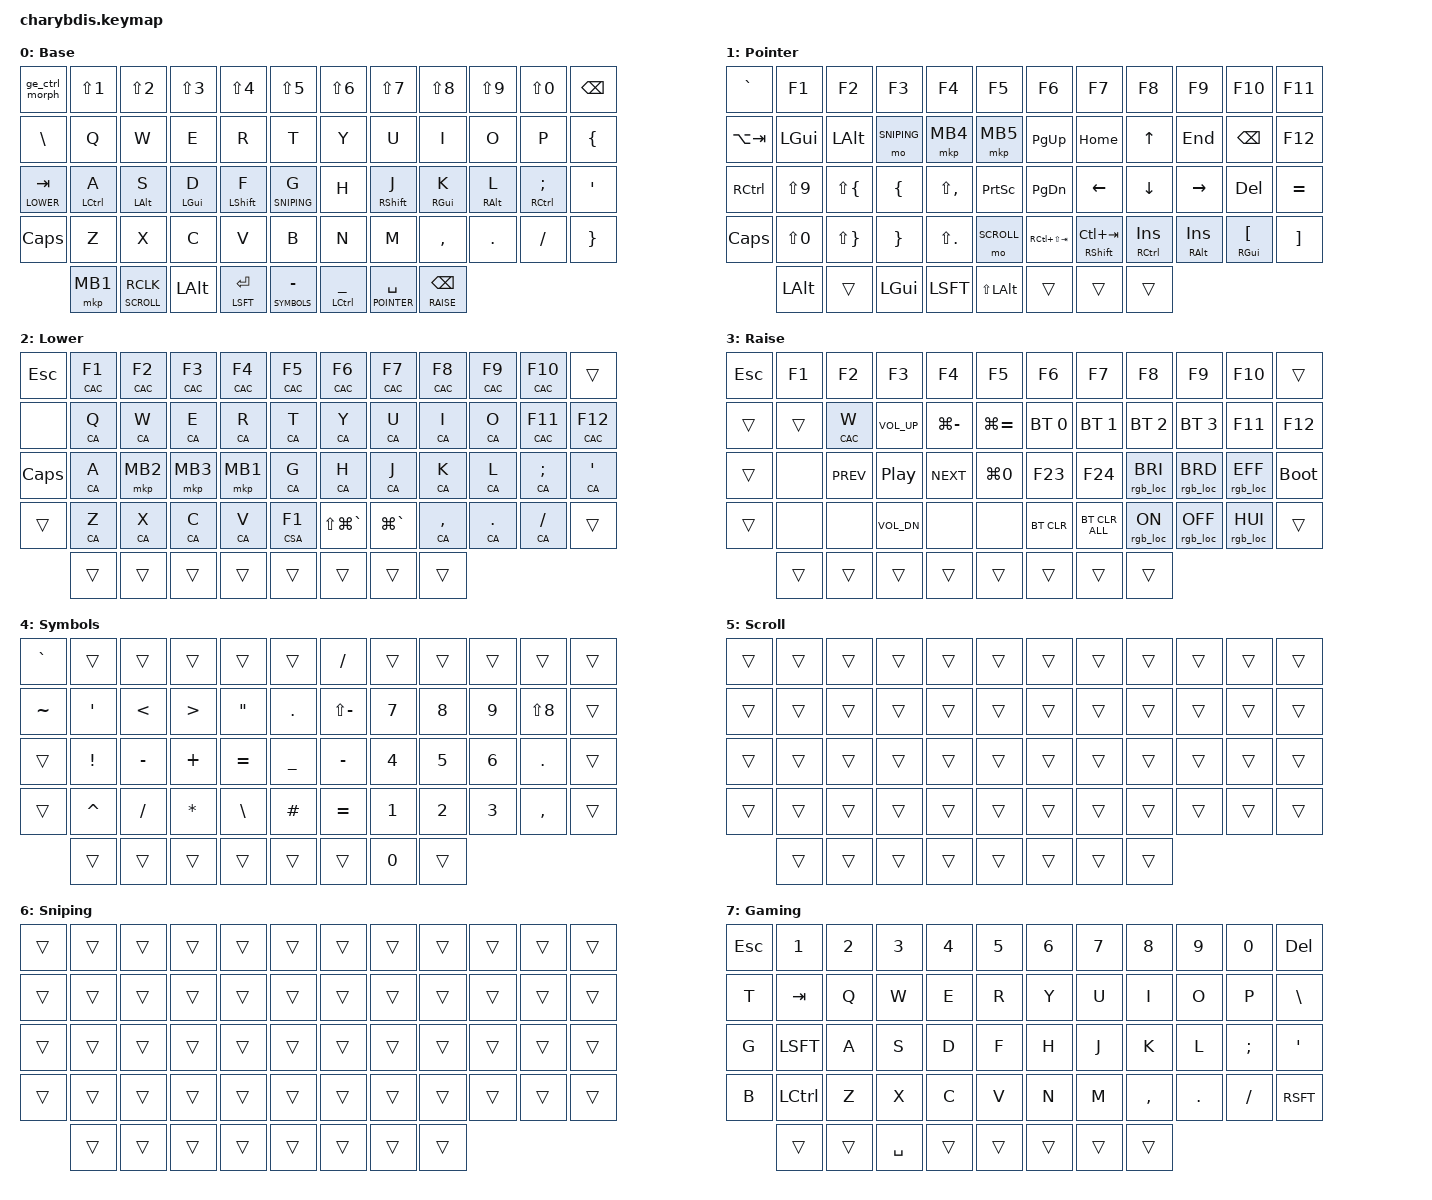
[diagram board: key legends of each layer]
#include <dt-bindings/zmk/mouse.h>
#include <behaviors/mouse_keys.dtsi>
#include <behaviors.dtsi>
#include <dt-bindings/zmk/bt.h>
#include <dt-bindings/zmk/keys.h>
#include <dt-bindings/zmk/modifiers.h>
#include <dt-bindings/zmk/outputs.h>
#include <dt-bindings/zmk/pointing.h>
#include <dt-bindings/zmk/rgb.h>

/ {
    chosen { zmk,physical-layout = &charybdis_6col_layout; };
};

&mt {
    quick-tap-ms = <200>;
    flavor = "tap-preferred";
    tapping-term-ms = <170>;
};

&lt {
    quick-tap-ms = <200>;
    flavor = "tap-preferred";
    tapping-term-ms = <170>;
};

// Layer definitions
#define BASE 0
#define POINTER 1
#define LOWER 2
#define RAISE 3
#define SYMBOLS 4
#define SCROLL 5
#define SNIPING 6
#define GAMING 7

/ {
  behaviors {
    // Hold-tap behavior for layer with tap-preferred
    blt: blt {
      compatible = "zmk,behavior-hold-tap";
      #binding-cells = <2>;
      flavor = "tap-preferred";
      tapping-term-ms = <200>;
      quick-tap-ms = <300>;
      require-prior-idle-ms = <100>;
      bindings = <&mo>, <&kp>;
    };

    // Tap-dance for GUI/Ctrl+B
    gui_ctrlb: gui_ctrlb {
      compatible = "zmk,behavior-tap-dance";
      #binding-cells = <0>;
      tapping-term-ms = <200>;
      bindings = <&kp LGUI>, <&kp LC(B)>;
    };

    // Tap/hold Alt, double-tap Ctrl+Shift+Z
    lalt_dt: lalt_dt {
      compatible = "zmk,behavior-tap-dance";
      #binding-cells = <0>;
      tapping-term-ms = <200>;
      bindings = <&kp LALT>, <&kp LC(LS(Z))>;
    };

    // Home row mods - Left hand
    hml: home_row_mod_left {
      compatible = "zmk,behavior-hold-tap";
      #binding-cells = <2>;
      flavor = "balanced";
      require-prior-idle-ms = <150>;
      tapping-term-ms = <280>;
      quick-tap-ms = <175>;
      bindings = <&kp>, <&kp>;
      hold-trigger-key-positions = <6 7 8 9 10 11 18 19 20 21 22 23 30 31 32 33 34 35 42 43 44 45 46 47 53 54 55>; // Right side keys
      hold-trigger-on-release;
    };

    // Home row mods - Right hand
    hmr: home_row_mod_right {
      compatible = "zmk,behavior-hold-tap";
      #binding-cells = <2>;
      flavor = "balanced";
      require-prior-idle-ms = <150>;
      tapping-term-ms = <280>;
      quick-tap-ms = <175>;
      bindings = <&kp>, <&kp>;
      hold-trigger-key-positions = <0 1 2 3 4 5 12 13 14 15 16 17 24 25 26 27 28 29 36 37 38 39 40 41 48 49 50 51 52>; // Left side keys
      hold-trigger-on-release;
    };

    // RGB controls routed globally so split halves stay in sync.
    rgb_loc: rgbloc {
      compatible = "zmk,behavior-rgb-local";
      #binding-cells = <2>;
    };

    // RGB controls: dedicated direct bindings.
    // 1. Сначала обрабатываем нажатие с Ctrl: если зажат Ctrl, отправляем `, иначе переходим к проверке Shift
    ge_ctrl_morph: ge_ctrl_morph {
        compatible = "zmk,behavior-mod-morph";
        #binding-cells = <0>;
        bindings = <&ge_shift_morph>, <&kp GRAVE>;
        mods = <(MOD_LCTL|MOD_RCTL)>;
        keep-mods = <0>; // Убирает Ctrl, чтобы напечатался чистый символ `
    };

    // 2. Проверяем Shift: если зажат Shift, отправляем ~, если ничего не зажато — отправляем ESC
    ge_shift_morph: ge_shift_morph {
        compatible = "zmk,behavior-mod-morph";
        #binding-cells = <0>;
        bindings = <&kp ESC>, <&kp TILDE>;
        mods = <(MOD_LSFT|MOD_RSFT)>;
        keep-mods = <0>; // Убирает Shift, чтобы напечаталась чистая тильда ~
    };  

    // Special behavior, smart analog of Layer-Tap, but here the second action is a mouse button
    blt_mouse: blt_mouse {
          compatible = "zmk,behavior-hold-tap";
          #binding-cells = <2>;
          flavor = "tap-preferred";
          tapping-term-ms = <200>;
          quick-tap-ms = <300>;
          require-prior-idle-ms = <100>;
          bindings = <&mo>, <&mkp>; // <- CRITICAL: keep &mkp instead of &kp
        };

  };

  macros {
    // Ctrl+Alt+Cmd macro
    CAC: CAC {
      compatible = "zmk,behavior-macro-one-param";
      #binding-cells = <1>;
      bindings
        = <&macro_press &kp LCTRL &kp LALT &kp LGUI>
        , <&macro_param_1to1>
        , <&macro_tap &kp MACRO_PLACEHOLDER>
        , <&macro_release &kp LCTRL &kp LALT &kp LGUI>
        ;
    };

    // Ctrl+Shift+Alt macro
    CSA: CSA {
      compatible = "zmk,behavior-macro-one-param";
      #binding-cells = <1>;
      bindings
        = <&macro_press &kp LCTRL &kp LSHIFT &kp LALT>
        , <&macro_param_1to1>
        , <&macro_tap &kp MACRO_PLACEHOLDER>
        , <&macro_release &kp LCTRL &kp LSHIFT &kp LALT>
        ;
    };

    // Ctrl+Alt macro
    CA: CA {
      compatible = "zmk,behavior-macro-one-param";
      #binding-cells = <1>;
      bindings
        = <&macro_press &kp LCTRL &kp LALT>
        , <&macro_param_1to1>
        , <&macro_tap &kp MACRO_PLACEHOLDER>
        , <&macro_release &kp LCTRL &kp LALT>
        ;
    };

    // Hold Ctrl+Cmd+Left Click while key is pressed (for mouse drag window actions)
    ctrl_cmd_hold: ctrl_cmd_hold {
      compatible = "zmk,behavior-macro";
      wait-ms = <0>;
      tap-ms = <10>;
      #binding-cells = <0>;
      bindings
        = <&macro_press &kp LCTRL &kp LGUI &mkp LCLK>
        , <&macro_pause_for_release>
        , <&macro_release &mkp LCLK &kp LCTRL &kp LGUI>
        ;
    };
  };

  combos {
    compatible = "zmk,combos";
    timeout-ms = <20>;
    require-prior-idle-ms = <250>;

    // Studio Unlock Combo - all three right thumb keys
    combo_studio_unlock {
      timeout-ms = <50>;
      key-positions = <53 54 55>;
      bindings = <&studio_unlock>;
    };

    // Gaming layer toggle combo - keys 49, 55, 54
    combo_gaming_toggle {
      timeout-ms = <50>;
      key-positions = <49 55 54>;
      bindings = <&tog GAMING>;
    };

  };

  keymap {
    compatible = "zmk,keymap";

// ╭─────────────┬─────────────┬─────────────┬─────────────┬─────────────┬─────────────╮   ╭─────────────┬─────────────┬─────────────┬─────────────┬─────────────┬─────────────╮
//    0             1             2             3             4             5                 6             7             8             9            10            11
// ├─────────────┼─────────────┼─────────────┼─────────────┼─────────────┼─────────────┤   ├─────────────┼─────────────┼─────────────┼─────────────┼─────────────┼─────────────┤
//   12            13            14            15            16            17                18            19            20            21            22            23
// ├─────────────┼─────────────┼─────────────┼─────────────┼─────────────┼─────────────┤   ├─────────────┼─────────────┼─────────────┼─────────────┼─────────────┼─────────────┤
//   24            25            26            27            28            29                30            31            32            33            34            35
// ├─────────────┼─────────────┼─────────────┼─────────────┼─────────────┼─────────────┤   ├─────────────┼─────────────┼─────────────┼─────────────┼─────────────┼─────────────┤
//   36            37            38            39            40            41                42            43            44            45            46            47
// ╰─────────────┴─────────────┴─────────────┴─────────────┴─────────────┴─────────────╯   ╰─────────────┴─────────────┴─────────────┴─────────────┴─────────────┴─────────────╯
//               ╭─────────────┬─────────────┬─────────────┬─────────────┬─────────────╮   ╭─────────────┬─────────────┬─────────────╮
//                  48            49            50            51            52                53            54            55
//               ╰─────────────┴─────────────┴─────────────┴─────────────┴─────────────╯   ╰─────────────┴─────────────┴─────────────╯
//                                                                         Actual Key Positions
//                                          ╭─────────────┬─────────────┬─────────────╮    ╭─────────────┬─────────────╮
//                                             50           51            48                 55            54
//                                          ╰─────────────┼─────────────┼─────────────┤    ├─────────────┼─────────────╯
//                                                          52            49                 53
//                                                        ╰─────────────┴─────────────╯    ╰─────────────╯

    base_layer {
      label = "BASE";
      display-name = "Base";
      bindings = <
// ╭─────────────┬─────────────┬─────────────┬─────────────┬─────────────┬─────────────╮   ╭─────────────┬─────────────┬─────────────┬─────────────┬─────────────┬─────────────╮
    &ge_ctrl_morph &kp LS(N1)    &kp LS(N2)    &kp LS(N3)    &kp LS(N4)    &kp LS(N5)        &kp LS(N6)    &kp LS(N7)    &kp LS(N8)    &kp LS(N9)    &kp LS(N0)    &kp BSPC
// ├─────────────┼─────────────┼─────────────┼─────────────┼─────────────┼─────────────┤   ├─────────────┼─────────────┼─────────────┼─────────────┼─────────────┼─────────────┤
    &kp BSLH      &kp Q         &kp W         &kp E         &kp R         &kp T             &kp Y         &kp U         &kp I         &kp O         &kp P         &kp LBRC
// ├─────────────┼─────────────┼─────────────┼─────────────┼─────────────┼─────────────┤   ├─────────────┼─────────────┼─────────────┼─────────────┼─────────────┼─────────────┤
    &blt LOWER TAB &hml LCTRL A &hml LALT S  &hml LGUI D   &hml LSHIFT F &blt SNIPING G    &kp H         &hmr RSHIFT J &hmr RGUI K   &hmr RALT L  &hmr RCTRL SEMI      &kp SQT
// ├─────────────┼─────────────┼─────────────┼─────────────┼─────────────┼─────────────┤   ├─────────────┼─────────────┼─────────────┼─────────────┼─────────────┼─────────────┤
    &kp CAPS      &kp Z         &kp X         &kp C         &kp V         &kp B             &kp N         &kp M         &kp COMMA     &kp DOT       &kp FSLH      &kp RBRC
// ╰─────────────┴─────────────┴─────────────┴─────────────┴─────────────┴─────────────╯   ╰─────────────┴─────────────┴─────────────┴─────────────┴─────────────┴─────────────╯
//               ╭─────────────┬─────────────┬─────────────┬─────────────┬─────────────╮   ╭─────────────┬─────────────┬─────────────╮
                  &mkp MB1     &blt_mouse SCROLL RCLK &kp LALT &mt LSFT RET &blt SYMBOLS MINUS &mt LCTRL UNDER &blt POINTER SPACE  &blt RAISE BSPC
//               ╰─────────────┴─────────────┴─────────────┴─────────────┴─────────────╯   ╰─────────────┴─────────────┴─────────────╯
      >;
    };

    pointer_layer {
      label = "POINTER";
      display-name = "Pointer";
      bindings = <
// ╭─────────────┬─────────────┬─────────────┬─────────────┬─────────────┬─────────────╮   ╭─────────────┬─────────────┬─────────────┬─────────────┬─────────────┬─────────────╮
    &kp GRAVE     &kp F1        &kp F2        &kp F3        &kp F4        &kp F5            &kp F6        &kp F7        &kp F8        &kp F9        &kp F10       &kp F11
// ├─────────────┼─────────────┼─────────────┼─────────────┼─────────────┼─────────────┤   ├─────────────┼─────────────┼─────────────┼─────────────┼─────────────┼─────────────┤
    &kp LA(TAB)   &kp LGUI      &kp LALT      &mo SNIPING   &mkp MB4      &mkp MB5          &kp PG_UP      &kp HOME     &kp UP        &kp END       &kp BSPC       &kp F12
// ├─────────────┼─────────────┼─────────────┼─────────────┼─────────────┼─────────────┤   ├─────────────┼─────────────┼─────────────┼─────────────┼─────────────┼─────────────┤
    &kp RCTRL     &kp LS(N9)    &kp LS(LBRC)  &kp LBRC      &kp LS(COMMA) &kp PSCRN         &kp PG_DN      &kp LEFT      &kp DOWN        &kp RIGHT     &kp DEL     &kp EQUAL
// ├─────────────┼─────────────┼─────────────┼─────────────┼─────────────┼─────────────┤   ├─────────────┼─────────────┼─────────────┼─────────────┼─────────────┼─────────────┤
    &kp CAPS      &kp LS(N0)    &kp LS(RBRC)  &kp RBRC      &kp LS(DOT)   &mo SCROLL        &kp RC(LS(TAB)) &hmr RSHIFT LC(TAB) &hmr RCTRL INS &hmr RALT INS &hmr RGUI LBKT &kp RBKT
// ╰─────────────┴─────────────┴─────────────┴─────────────┴─────────────┴─────────────╯   ╰─────────────┴─────────────┴─────────────┴─────────────┴─────────────┴─────────────╯
//               ╭─────────────┬─────────────┬─────────────┬─────────────┬─────────────╮   ╭─────────────┬─────────────┬─────────────╮
                  &kp LALT      &trans        &kp LGUI      &kp LSFT      &kp LS(LALT)      &trans        &trans        &trans
//               ╰─────────────┴─────────────┴─────────────┴─────────────┴─────────────╯   ╰─────────────┴─────────────┴─────────────╯
      >;
    };

    lower_layer {
      label = "LOWER";
      display-name = "Lower";
      bindings = <
// ╭─────────────┬─────────────┬─────────────┬─────────────┬─────────────┬─────────────╮   ╭─────────────┬─────────────┬─────────────┬─────────────┬─────────────┬─────────────╮
    &kp ESC       &CAC F1       &CAC F2       &CAC F3       &CAC F4       &CAC F5           &CAC F6       &CAC F7       &CAC F8       &CAC F9       &CAC F10      &trans
// ├─────────────┼─────────────┼─────────────┼─────────────┼─────────────┼─────────────┤   ├─────────────┼─────────────┼─────────────┼─────────────┼─────────────┼─────────────┤
    &none         &CA Q         &CA W         &CA E         &CA R         &CA T             &CA Y         &CA U         &CA I         &CA O         &CAC F11      &CAC F12
// ├─────────────┼─────────────┼─────────────┼─────────────┼─────────────┼─────────────┤   ├─────────────┼─────────────┼─────────────┼─────────────┼─────────────┼─────────────┤
    &kp CAPS      &CA A         &mkp MB2      &mkp MB3      &mkp MB1      &CA G             &CA H         &CA J         &CA K         &CA L         &CA SEMI      &CA SQT
// ├─────────────┼─────────────┼─────────────┼─────────────┼─────────────┼─────────────┤   ├─────────────┼─────────────┼─────────────┼─────────────┼─────────────┼─────────────┤
    &trans        &CA Z         &CA X         &CA C         &CA V         &CSA F1           &kp LS(LG(GRAVE)) &kp LG(GRAVE) &CA COMMA     &CA DOT       &CA FSLH      &trans
// ╰─────────────┴─────────────┴─────────────┴─────────────┴─────────────┴─────────────╯   ╰─────────────┴─────────────┴─────────────┴─────────────┴─────────────┴─────────────╯
//               ╭─────────────┬─────────────┬─────────────┬─────────────┬─────────────╮   ╭─────────────┬─────────────┬─────────────╮
                  &trans        &trans        &trans        &trans        &trans            &trans        &trans        &trans
//               ╰─────────────┴─────────────┴─────────────┴─────────────┴─────────────╯   ╰─────────────┴─────────────┴─────────────╯
      >;
    };

    raise_layer {
      label = "RAISE";
      display-name = "Raise";
      bindings = <
// ╭─────────────┬─────────────┬─────────────┬─────────────┬─────────────┬─────────────╮   ╭─────────────┬─────────────┬─────────────┬─────────────┬─────────────┬─────────────╮
    &kp ESC       &kp F1        &kp F2        &kp F3        &kp F4        &kp F5            &kp F6        &kp F7        &kp F8        &kp F9        &kp F10       &trans
// ├─────────────┼─────────────┼─────────────┼─────────────┼─────────────┼─────────────┤   ├─────────────┼─────────────┼─────────────┼─────────────┼─────────────┼─────────────┤
    &trans        &trans       &CAC W        &kp C_VOL_UP  &kp LG(MINUS) &kp LG(EQUAL)     &bt BT_SEL 0  &bt BT_SEL 1  &bt BT_SEL 2  &bt BT_SEL 3  &kp F11       &kp F12
// ├─────────────┼─────────────┼─────────────┼─────────────┼─────────────┼─────────────┤   ├─────────────┼─────────────┼─────────────┼─────────────┼─────────────┼─────────────┤
    &trans        &none         &kp C_PREV    &kp C_PP      &kp C_NEXT    &kp LG(N0)        &kp F23       &kp F24       &rgb_loc RGB_BRI &rgb_loc RGB_BRD &rgb_loc RGB_EFF &bootloader
// ├─────────────┼─────────────┼─────────────┼─────────────┼─────────────┼─────────────┤   ├─────────────┼─────────────┼─────────────┼─────────────┼─────────────┼─────────────┤
    &trans        &none         &none         &kp C_VOL_DN  &none         &none             &bt BT_CLR    &bt BT_CLR_ALL &rgb_loc RGB_ON &rgb_loc RGB_OFF &rgb_loc RGB_HUI &trans
// ╰─────────────┴─────────────┴─────────────┴─────────────┴─────────────┴─────────────╯   ╰─────────────┴─────────────┴─────────────┴─────────────┴─────────────┴─────────────╯
//               ╭─────────────┬─────────────┬─────────────┬─────────────┬─────────────╮   ╭─────────────┬─────────────┬─────────────╮
                    &trans        &trans        &trans        &trans        &trans            &trans        &trans        &trans
//               ╰─────────────┴─────────────┴─────────────┴─────────────┴─────────────╯   ╰─────────────┴─────────────┴─────────────╯
      >;
    };

    symbols_layer {
      label = "SYMBOLS";
      display-name = "Symbols";
      bindings = <
// ╭─────────────┬─────────────┬─────────────┬─────────────┬─────────────┬─────────────╮   ╭─────────────┬─────────────┬─────────────┬─────────────┬─────────────┬─────────────╮
    &kp GRAVE     &trans        &trans        &trans        &trans        &trans            &kp SLASH     &trans        &trans        &trans        &trans        &trans
// ├─────────────┼─────────────┼─────────────┼─────────────┼─────────────┼─────────────┤   ├─────────────┼─────────────┼─────────────┼─────────────┼─────────────┼─────────────┤
    &kp TILDE     &kp SQT       &kp LT        &kp GT        &kp DQT       &kp DOT           &kp LS(MINUS) &kp N7        &kp N8        &kp N9        &kp LS(N8)    &trans
// ├─────────────┼─────────────┼─────────────┼─────────────┼─────────────┼─────────────┤   ├─────────────┼─────────────┼─────────────┼─────────────┼─────────────┼─────────────┤
    &trans        &kp EXCL      &kp MINUS     &kp PLUS      &kp EQUAL     &kp UNDER         &kp MINUS     &kp N4        &kp N5        &kp N6        &kp DOT       &trans
// ├─────────────┼─────────────┼─────────────┼─────────────┼─────────────┼─────────────┤   ├─────────────┼─────────────┼─────────────┼─────────────┼─────────────┼─────────────┤
    &trans        &kp CARET     &kp FSLH      &kp ASTRK     &kp BSLH      &kp HASH          &kp EQUAL     &kp N1        &kp N2        &kp N3        &kp COMMA     &trans
// ╰─────────────┴─────────────┴─────────────┴─────────────┴─────────────┴─────────────╯   ╰─────────────┴─────────────┴─────────────┴─────────────┴─────────────┴─────────────╯
//               ╭─────────────┬─────────────┬─────────────┬─────────────┬─────────────╮   ╭─────────────┬─────────────┬─────────────╮
                    &trans        &trans        &trans        &trans        &trans            &trans        &kp N0        &trans
//               ╰─────────────┴─────────────┴─────────────┴─────────────┴─────────────╯   ╰─────────────┴─────────────┴─────────────╯
      >;
    };

    scroll_layer {
      label = "SCROLL";
      display-name = "Scroll";
      bindings = <
// ╭─────────────┬─────────────┬─────────────┬─────────────┬─────────────┬─────────────╮   ╭─────────────┬─────────────┬─────────────┬─────────────┬─────────────┬─────────────╮
    &trans        &trans        &trans        &trans        &trans        &trans            &trans        &trans        &trans        &trans        &trans        &trans
// ├─────────────┼─────────────┼─────────────┼─────────────┼─────────────┼─────────────┤   ├─────────────┼─────────────┼─────────────┼─────────────┼─────────────┼─────────────┤
    &trans        &trans        &trans        &trans        &trans        &trans            &trans        &trans        &trans        &trans        &trans        &trans
// ├─────────────┼─────────────┼─────────────┼─────────────┼─────────────┼─────────────┤   ├─────────────┼─────────────┼─────────────┼─────────────┼─────────────┼─────────────┤
    &trans        &trans        &trans        &trans        &trans        &trans            &trans        &trans        &trans        &trans        &trans        &trans
// ├─────────────┼─────────────┼─────────────┼─────────────┼─────────────┼─────────────┤   ├─────────────┼─────────────┼─────────────┼─────────────┼─────────────┼─────────────┤
    &trans        &trans        &trans        &trans        &trans        &trans            &trans        &trans        &trans        &trans        &trans        &trans
// ╰─────────────┴─────────────┴─────────────┴─────────────┴─────────────┴─────────────╯   ╰─────────────┴─────────────┴─────────────┴─────────────┴─────────────┴─────────────╯
//               ╭─────────────┬─────────────┬─────────────┬─────────────┬─────────────╮   ╭─────────────┬─────────────┬─────────────╮
                    &trans        &trans        &trans        &trans        &trans            &trans        &trans        &trans
//               ╰─────────────┴─────────────┴─────────────┴─────────────┴─────────────╯   ╰─────────────┴─────────────┴─────────────╯
      >;
    };

    sniping_layer {
      label = "SNIPING";
      display-name = "Sniping";
      bindings = <
// ╭─────────────┬─────────────┬─────────────┬─────────────┬─────────────┬─────────────╮   ╭─────────────┬─────────────┬─────────────┬─────────────┬─────────────┬─────────────╮
    &trans        &trans        &trans        &trans        &trans        &trans            &trans        &trans        &trans        &trans        &trans        &trans
// ├─────────────┼─────────────┼─────────────┼─────────────┼─────────────┼─────────────┤   ├─────────────┼─────────────┼─────────────┼─────────────┼─────────────┼─────────────┤
    &trans        &trans        &trans        &trans        &trans        &trans            &trans        &trans        &trans        &trans        &trans        &trans
// ├─────────────┼─────────────┼─────────────┼─────────────┼─────────────┼─────────────┤   ├─────────────┼─────────────┼─────────────┼─────────────┼─────────────┼─────────────┤
    &trans        &trans        &trans        &trans        &trans        &trans            &trans        &trans        &trans        &trans        &trans        &trans
// ├─────────────┼─────────────┼─────────────┼─────────────┼─────────────┼─────────────┤   ├─────────────┼─────────────┼─────────────┼─────────────┼─────────────┼─────────────┤
    &trans        &trans        &trans        &trans        &trans        &trans            &trans        &trans        &trans        &trans        &trans        &trans
// ╰─────────────┴─────────────┴─────────────┴─────────────┴─────────────┴─────────────╯   ╰─────────────┴─────────────┴─────────────┴─────────────┴─────────────┴─────────────╯
//               ╭─────────────┬─────────────┬─────────────┬─────────────┬─────────────╮   ╭─────────────┬─────────────┬─────────────╮
                    &trans        &trans        &trans        &trans        &trans            &trans        &trans        &trans
//               ╰─────────────┴─────────────┴─────────────┴─────────────┴─────────────╯   ╰─────────────┴─────────────┴─────────────╯
      >;
    };

    gaming_layer {
      label = "GAMING";
      display-name = "Gaming";
      bindings = <
// ╭─────────────┬─────────────┬─────────────┬─────────────┬─────────────┬─────────────╮   ╭─────────────┬─────────────┬─────────────┬─────────────┬─────────────┬─────────────╮
    &kp ESC       &kp N1       &kp N2        &kp N3        &kp N4        &kp N5            &kp N6        &kp N7        &kp N8        &kp N9        &kp N0        &kp DEL
// ├─────────────┼─────────────┼─────────────┼─────────────┼─────────────┼─────────────┤   ├─────────────┼─────────────┼─────────────┼─────────────┼─────────────┼─────────────┤
    &kp T        &kp TAB       &kp Q         &kp W         &kp E         &kp R             &kp Y         &kp U         &kp I         &kp O         &kp P         &kp BSLH
// ├─────────────┼─────────────┼─────────────┼─────────────┼─────────────┼─────────────┤   ├─────────────┼─────────────┼─────────────┼─────────────┼─────────────┼─────────────┤
    &kp G        &kp LSFT      &kp A         &kp S         &kp D         &kp F             &kp H         &kp J         &kp K         &kp L         &kp SEMI      &kp SQT
// ├─────────────┼─────────────┼─────────────┼─────────────┼─────────────┼─────────────┤   ├─────────────┼─────────────┼─────────────┼─────────────┼─────────────┼─────────────┤
    &kp B        &kp LCTRL     &kp Z         &kp X         &kp C         &kp V             &kp N         &kp M         &kp COMMA     &kp DOT       &kp FSLH      &kp RSFT
// ╰─────────────┴─────────────┴─────────────┴─────────────┴─────────────┴─────────────╯   ╰─────────────┴─────────────┴─────────────┴─────────────┴─────────────┴─────────────╯
//               ╭─────────────┬─────────────┬─────────────┬─────────────┬─────────────╮   ╭─────────────┬─────────────┬─────────────╮
                  &trans        &trans        &kp SPACE     &trans        &trans            &trans        &trans        &trans
//               ╰─────────────┴─────────────┴─────────────┴─────────────┴─────────────╯   ╰─────────────┴─────────────┴─────────────╯
      >;
    };
  };
};
